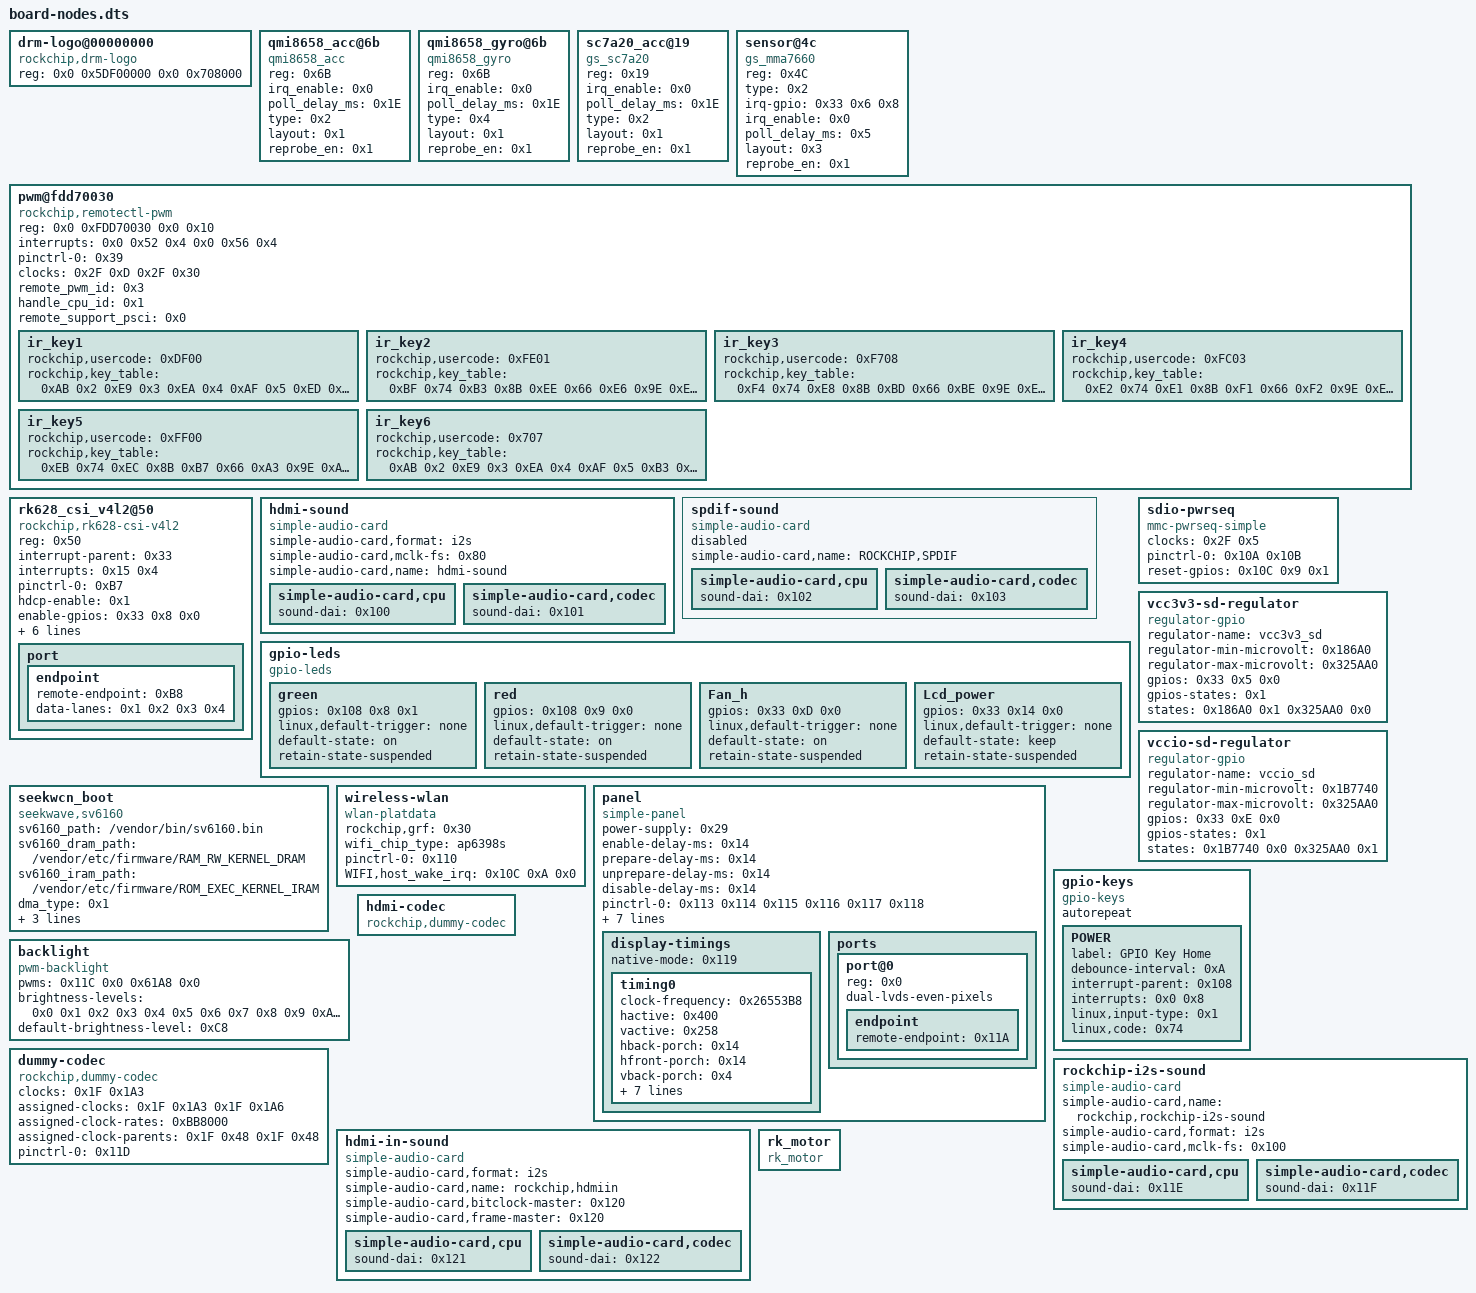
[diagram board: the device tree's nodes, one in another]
/* Nós específicos da placa HY300 RK3566 extraídos do DT vivo (sanitizado).
   Phandles numéricos: consultar rk3566-hy300-txcz-live.dts. */

// ---- rockchip,drm-logo
        drm-logo@00000000 {
            compatible = "rockchip,drm-logo";
            reg = <0x0 0x5DF00000 0x0 0x708000>;
            phandle = <0x11>;
        };

// ---- qmi8658_acc
        qmi8658_acc@6b {
            compatible = "qmi8658_acc";
            reg = <0x6B>;
            irq_enable = <0x0>;
            poll_delay_ms = <0x1E>;
            type = <0x2>;
            layout = <0x1>;
            reprobe_en = <0x1>;
            status = "okay";
        };

// ---- qmi8658_gyro
        qmi8658_gyro@6b {
            compatible = "qmi8658_gyro";
            reg = <0x6B>;
            irq_enable = <0x0>;
            poll_delay_ms = <0x1E>;
            type = <0x4>;
            layout = <0x1>;
            reprobe_en = <0x1>;
            status = "okay";
        };

// ---- gs_sc7a20
        sc7a20_acc@19 {
            compatible = "gs_sc7a20";
            reg = <0x19>;
            irq_enable = <0x0>;
            poll_delay_ms = <0x1E>;
            type = <0x2>;
            layout = <0x1>;
            reprobe_en = <0x1>;
            status = "okay";
        };

// ---- gs_mma7660
        sensor@4c {
            status = "okay";
            compatible = "gs_mma7660";
            reg = <0x4C>;
            type = <0x2>;
            irq-gpio = <0x33 0x6 0x8>;
            irq_enable = <0x0>;
            poll_delay_ms = <0x5>;
            layout = <0x3>;
            reprobe_en = <0x1>;
        };

// ---- rockchip,remotectl-pwm
    pwm@fdd70030 {
        compatible = "rockchip,remotectl-pwm";
        reg = <0x0 0xFDD70030 0x0 0x10>;
        interrupts = <0x0 0x52 0x4 0x0 0x56 0x4>;
        #pwm-cells = <0x3>;
        pinctrl-names = "default";
        pinctrl-0 = <0x39>;
        clocks = <0x2F 0xD 0x2F 0x30>;
        clock-names = "pwm", "pclk";
        status = "okay";
        remote_pwm_id = <0x3>;
        handle_cpu_id = <0x1>;
        remote_support_psci = <0x0>;
        phandle = <0x154>;
        ir_key1 {
            rockchip,usercode = <0xDF00>;
            rockchip,key_table = <0xAB 0x2 0xE9 0x3 0xEA 0x4 0xAF 0x5 0xED 0x6 0xB3 0x8 0xF1 0x9 0xF2 0xA 0xF3 0xB 0xE3 0x74 0xE7 0x8B 0xFC 0x66 0xF5 0x9E 0xB0 0x72 0xB4 0x73 0xA5 0x71 0xF9 0xE8 0xE5 0x67 0xB7 0x6C 0xB8 0x69 0xF8 0x6A 0xEF 0x41 0xEE 0x184 0xA2 0x57 0xA3 0x58 0xE4 0xB9 0xB6 0xBA 0xA0 0xB6 0x8B 0xB8 0xBD 0xBB>;
        };
        ir_key2 {
            rockchip,usercode = <0xFE01>;
            rockchip,key_table = <0xBF 0x74 0xB3 0x8B 0xEE 0x66 0xE6 0x9E 0xEF 0x72 0xE7 0x73 0xEC 0xE8 0xE9 0x67 0xE5 0x6C 0xAE 0x69 0xAF 0x6A 0xF0 0xBB 0xBE 0x71 0xBC 0xBC 0xFF 0x184>;
        };
        ir_key3 {
            rockchip,usercode = <0xF708>;
            rockchip,key_table = <0xF4 0x74 0xE8 0x8B 0xBD 0x66 0xBE 0x9E 0xE3 0x72 0xF1 0x73 0xE1 0xE8 0xED 0x67 0xEC 0x6C 0xEA 0x69 0x7 0xB4 0xE 0xB8 0xEB 0x6A>;
        };
        ir_key4 {
            rockchip,usercode = <0xFC03>;
            rockchip,key_table = <0xE2 0x74 0xE1 0x8B 0xF1 0x66 0xF2 0x9E 0xEA 0x72 0xEE 0x73 0xF4 0xE8 0xF6 0x67 0xFE 0x6C 0xF5 0x69 0xF7 0x6A 0xE6 0xBB 0xFD 0x71 0xF8 0xBC 0xFA 0x184>;
        };
        ir_key5 {
            rockchip,usercode = <0xFF00>;
            rockchip,key_table = <0xEB 0x74 0xEC 0x8B 0xB7 0x66 0xA3 0x9E 0xA7 0x72 0xF4 0x73 0xF8 0xE8 0xFC 0x67 0xFD 0x6C 0xF1 0x69 0xE5 0x6A 0x6C 0xBB 0xFE 0x71 0x67 0xBC 0x7D 0x184>;
        };
        ir_key6 {
            rockchip,usercode = <0x707>;
            rockchip,key_table = <0xAB 0x2 0xE9 0x3 0xEA 0x4 0xAF 0x5 0xB3 0x8 0xF1 0x9 0xF2 0xA 0xF3 0xB 0xFD 0x74 0xE5 0x8B 0xC1 0x66 0xD2 0x9E 0xF4 0x72 0xF8 0x73 0xF0 0x71 0x97 0xE8 0x9F 0x67 0x9E 0x6C 0x9A 0x69 0x9D 0x6A 0x7D 0x184 0xA2 0x57 0xA3 0xBB 0xED 0xB9 0xEF 0xBA 0xA0 0xB6 0x8B 0xB8 0x77 0xBD>;
        };
    };

// ---- rockchip,rk628-csi-v4l2
        rk628_csi_v4l2@50 {
            reg = <0x50>;
            compatible = "rockchip,rk628-csi-v4l2";
            interrupt-parent = <0x33>;
            interrupts = <0x15 0x4>;
            pinctrl-names = "default";
            pinctrl-0 = <0xB7>;
            hdcp-enable = <0x1>;
            enable-gpios = <0x33 0x8 0x0>;
            reset-gpios = <0x33 0x17 0x1>;
            plugin-det-gpios = <0x33 0x16 0x1>;
            rockchip,camera-module-index = <0x0>;
            rockchip,camera-module-facing = "back";
            rockchip,camera-module-name = "RK628-CSI";
            rockchip,camera-module-lens-name = "NC";
            phandle = <0x18E>;
            port {
                endpoint {
                    remote-endpoint = <0xB8>;
                    data-lanes = <0x1 0x2 0x3 0x4>;
                    phandle = <0xEF>;
                };
            };
        };

// ---- simple-audio-card
    hdmi-sound {
        compatible = "simple-audio-card";
        simple-audio-card,format = "i2s";
        simple-audio-card,mclk-fs = <0x80>;
        simple-audio-card,name = "hdmi-sound";
        status = "okay";
        phandle = <0x1B2>;
        simple-audio-card,cpu {
            sound-dai = <0x100>;
        };
        simple-audio-card,codec {
            sound-dai = <0x101>;
        };
    };

// ---- simple-audio-card
    spdif-sound {
        status = "disabled";
        compatible = "simple-audio-card";
        simple-audio-card,name = "ROCKCHIP,SPDIF";
        simple-audio-card,cpu {
            sound-dai = <0x102>;
        };
        simple-audio-card,codec {
            sound-dai = <0x103>;
        };
    };

// ---- gpio-leds
    gpio-leds {
        compatible = "gpio-leds";
        green {
            gpios = <0x108 0x8 0x1>;
            linux,default-trigger = "none";
            default-state = "on";
            retain-state-suspended;
        };
        red {
            gpios = <0x108 0x9 0x0>;
            linux,default-trigger = "none";
            default-state = "on";
            retain-state-suspended;
        };
        Fan_h {
            gpios = <0x33 0xD 0x0>;
            linux,default-trigger = "none";
            default-state = "on";
            retain-state-suspended;
        };
        Lcd_power {
            gpios = <0x33 0x14 0x0>;
            linux,default-trigger = "none";
            default-state = "keep";
            retain-state-suspended;
        };
    };

// ---- mmc-pwrseq-simple
    sdio-pwrseq {
        compatible = "mmc-pwrseq-simple";
        clocks = <0x2F 0x5>;
        clock-names = "ext_clock";
        pinctrl-names = "default";
        pinctrl-0 = <0x10A 0x10B>;
        reset-gpios = <0x10C 0x9 0x1>;
        phandle = <0x9B>;
    };

// ---- regulator-gpio
    vcc3v3-sd-regulator {
        compatible = "regulator-gpio";
        regulator-name = "vcc3v3_sd";
        regulator-min-microvolt = <0x186A0>;
        regulator-max-microvolt = <0x325AA0>;
        gpios = <0x33 0x5 0x0>;
        gpios-states = <0x1>;
        states = <0x186A0 0x1 0x325AA0 0x0>;
        phandle = <0x95>;
    };

// ---- regulator-gpio
    vccio-sd-regulator {
        compatible = "regulator-gpio";
        regulator-name = "vccio_sd";
        regulator-min-microvolt = <0x1B7740>;
        regulator-max-microvolt = <0x325AA0>;
        gpios = <0x33 0xE 0x0>;
        gpios-states = <0x1>;
        states = <0x1B7740 0x0 0x325AA0 0x1>;
        phandle = <0x96>;
    };

// ---- seekwave,sv6160
    seekwcn_boot {
        compatible = "seekwave,sv6160";
        sv6160_path = "/vendor/bin/sv6160.bin";
        sv6160_dram_path = "/vendor/etc/firmware/RAM_RW_KERNEL_DRAM";
        sv6160_iram_path = "/vendor/etc/firmware/ROM_EXEC_KERNEL_IRAM";
        dma_type = <0x1>;
        status = "okay";
        gpio_host_wake = <0x10C 0xF 0x1>;
        gpio_chip_wake = <0x10C 0xA 0x0>;
        gpio_chip_en = <0x10C 0x9 0x0>;
        phandle = <0x1B5>;
    };

// ---- wlan-platdata
    wireless-wlan {
        compatible = "wlan-platdata";
        rockchip,grf = <0x30>;
        wifi_chip_type = "ap6398s";
        pinctrl-names = "default";
        pinctrl-0 = <0x110>;
        WIFI,host_wake_irq = <0x10C 0xA 0x0>;
        status = "okay";
        phandle = <0x1B6>;
    };

// ---- simple-panel
    panel {
        compatible = "simple-panel";
        power-supply = <0x29>;
        enable-delay-ms = <0x14>;
        prepare-delay-ms = <0x14>;
        unprepare-delay-ms = <0x14>;
        disable-delay-ms = <0x14>;
        pinctrl-names = "default";
        pinctrl-0 = <0x113 0x114 0x115 0x116 0x117 0x118>;
        spi-sdi-gpios = <0x108 0x1D 0x1>;
        spi-scl-gpios = <0x108 0x1E 0x0>;
        spi-cs-gpios = <0x108 0x1F 0x0>;
        reset-gpios = <0x10C 0x1 0x1>;
        enable-gpios = <0x10C 0x2 0x0>;
        width-mm = <0xD9>;
        height-mm = <0x88>;
        display-timings {
            native-mode = <0x119>;
            timing0 {
                clock-frequency = <0x26553B8>;
                hactive = <0x400>;
                vactive = <0x258>;
                hback-porch = <0x14>;
                hfront-porch = <0x14>;
                vback-porch = <0x4>;
                vfront-porch = <0xA>;
                hsync-len = <0x14>;
                vsync-len = <0x4>;
                hsync-active = <0x0>;
                vsync-active = <0x0>;
                de-active = <0x0>;
                pixelclk-active = <0x0>;
                phandle = <0x119>;
            };
        };
        ports {
            #address-cells = <0x1>;
            #size-cells = <0x0>;
            port@0 {
                reg = <0x0>;
                dual-lvds-even-pixels;
                endpoint {
                    remote-endpoint = <0x11A>;
                    phandle = <0x2D>;
                };
            };
        };
    };

// ---- gpio-keys
    gpio-keys {
        status = "okay";
        compatible = "gpio-keys";
        autorepeat;
        phandle = <0x1BB>;
        POWER {
            label = "GPIO Key Home";
            debounce-interval = <0xA>;
            interrupt-parent = <0x108>;
            interrupts = <0x0 0x8>;
            linux,input-type = <0x1>;
            linux,code = <0x74>;
        };
    };

// ---- pwm-backlight
    backlight {
        compatible = "pwm-backlight";
        pwms = <0x11C 0x0 0x61A8 0x0>;
        brightness-levels = <0x0 0x1 0x2 0x3 0x4 0x5 0x6 0x7 0x8 0x9 0xA 0xB 0xC 0xD 0xE 0xF 0x10 0x11 0x12 0x13 0x14 0x15 0x16 0x17 0x18 0x19 0x1A 0x1B 0x1C 0x1D 0x1E 0x1F 0x20 0x21 0x22 0x23 0x24 0x25 0x26 0x27 0x28 0x29 0x2A 0x2B 0x2C 0x2D 0x2E 0x2F 0x30 0x31 0x32 0x33 0x34 0x35 0x36 0x37 0x38 0x39 0x3A 0x3B 0x3C 0x3D 0x3E 0x3F 0x40 0x41 0x42 0x43 0x44 0x45 0x46 0x47 0x48 0x49 0x4A 0x4B 0x4C 0x4D 0x4E 0x4F 0x50 0x51 0x52 0x53 0x54 0x55 0x56 0x57 0x58 0x59 0x5A 0x5B 0x5C 0x5D 0x5E 0x5F 0x60 0x61 0x62 0x63 0x64 0x65 0x66 0x67 0x68 0x69 0x6A 0x6B 0x6C 0x6D 0x6E 0x6F 0x70 0x71 0x72 0x73 0x74 0x75 0x76 0x77 0x78 0x79 0x7A 0x7B 0x7C 0x7D 0x7E 0x7F 0x80 0x81 0x82 0x83 0x84 0x85 0x86 0x87 0x88 0x89 0x8A 0x8B 0x8C 0x8D 0x8E 0x8F 0x90 0x91 0x92 0x93 0x94 0x95 0x96 0x97 0x98 0x99 0x9A 0x9B 0x9C 0x9D 0x9E 0x9F 0xA0 0xA1 0xA2 0xA3 0xA4 0xA5 0xA6 0xA7 0xA8 0xA9 0xAA 0xAB 0xAC 0xAD 0xAE 0xAF 0xB0 0xB1 0xB2 0xB3 0xB4 0xB5 0xB6 0xB7 0xB8 0xB9 0xBA 0xBB 0xBC 0xBD 0xBE 0xBF 0xC0 0xC1 0xC2 0xC3 0xC4 0xC5 0xC6 0xC7 0xC8 0xC9 0xCA 0xCB 0xCC 0xCD 0xCE 0xCF 0xD0 0xD1 0xD2 0xD3 0xD4 0xD5 0xD6 0xD7 0xD8 0xD9 0xDA 0xDB 0xDC 0xDD 0xDE 0xDF 0xE0 0xE1 0xE2 0xE3 0xE4 0xE5 0xE6 0xE7 0xE8 0xE9 0xEA 0xEB 0xEC 0xED 0xEE 0xEF 0xF0 0xF1 0xF2 0xF3 0xF4 0xF5 0xF6 0xF7 0xF8 0xF9 0xFA 0xFB 0xFC 0xFD 0xFE 0xFF>;
        default-brightness-level = <0xC8>;
        phandle = <0x1BD>;
    };

// ---- rockchip,dummy-codec
    dummy-codec {
        status = "okay";
        compatible = "rockchip,dummy-codec";
        #sound-dai-cells = <0x0>;
        clocks = <0x1F 0x1A3>;
        clock-names = "mclk";
        assigned-clocks = <0x1F 0x1A3 0x1F 0x1A6>;
        assigned-clock-rates = <0xBB8000>;
        assigned-clock-parents = <0x1F 0x48 0x1F 0x48>;
        pinctrl-names = "default";
        pinctrl-0 = <0x11D>;
        phandle = <0x11F>;
    };

// ---- simple-audio-card
    rockchip-i2s-sound {
        status = "okay";
        compatible = "simple-audio-card";
        simple-audio-card,name = "rockchip,rockchip-i2s-sound";
        simple-audio-card,format = "i2s";
        simple-audio-card,mclk-fs = <0x100>;
        phandle = <0x1BE>;
        simple-audio-card,cpu {
            sound-dai = <0x11E>;
        };
        simple-audio-card,codec {
            sound-dai = <0x11F>;
        };
    };

// ---- rockchip,dummy-codec
    hdmi-codec {
        status = "okay";
        compatible = "rockchip,dummy-codec";
        #sound-dai-cells = <0x0>;
        phandle = <0x122>;
    };

// ---- simple-audio-card
    hdmi-in-sound {
        status = "okay";
        compatible = "simple-audio-card";
        simple-audio-card,format = "i2s";
        simple-audio-card,name = "rockchip,hdmiin";
        simple-audio-card,bitclock-master = <0x120>;
        simple-audio-card,frame-master = <0x120>;
        phandle = <0x1BF>;
        simple-audio-card,cpu {
            sound-dai = <0x121>;
        };
        simple-audio-card,codec {
            sound-dai = <0x122>;
            phandle = <0x120>;
        };
    };

// ---- rk_motor
    rk_motor {
        compatible = "rk_motor", "usb-cam-gpio";
    };
